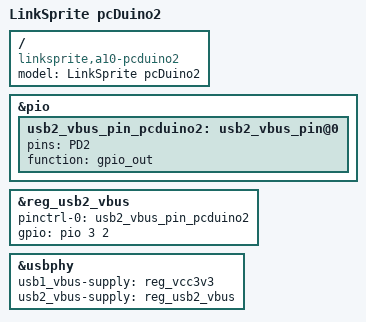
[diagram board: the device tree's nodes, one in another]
/*
 * Copyright 2015 Siarhei Siamashka <siarhei.siamashka@gmail.com>
 *
 * This file is dual-licensed: you can use it either under the terms
 * of the GPL or the X11 license, at your option. Note that this dual
 * licensing only applies to this file, and not this project as a
 * whole.
 *
 *  a) This file is free software; you can redistribute it and/or
 *     modify it under the terms of the GNU General Public License as
 *     published by the Free Software Foundation; either version 2 of the
 *     License, or (at your option) any later version.
 *
 *     This file is distributed in the hope that it will be useful,
 *     but WITHOUT ANY WARRANTY; without even the implied warranty of
 *     MERCHANTABILITY or FITNESS FOR A PARTICULAR PURPOSE.  See the
 *     GNU General Public License for more details.
 *
 * Or, alternatively,
 *
 *  b) Permission is hereby granted, free of charge, to any person
 *     obtaining a copy of this software and associated documentation
 *     files (the "Software"), to deal in the Software without
 *     restriction, including without limitation the rights to use,
 *     copy, modify, merge, publish, distribute, sublicense, and/or
 *     sell copies of the Software, and to permit persons to whom the
 *     Software is furnished to do so, subject to the following
 *     conditions:
 *
 *     The above copyright notice and this permission notice shall be
 *     included in all copies or substantial portions of the Software.
 *
 *     THE SOFTWARE IS PROVIDED "AS IS", WITHOUT WARRANTY OF ANY KIND,
 *     EXPRESS OR IMPLIED, INCLUDING BUT NOT LIMITED TO THE WARRANTIES
 *     OF MERCHANTABILITY, FITNESS FOR A PARTICULAR PURPOSE AND
 *     NONINFRINGEMENT. IN NO EVENT SHALL THE AUTHORS OR COPYRIGHT
 *     HOLDERS BE LIABLE FOR ANY CLAIM, DAMAGES OR OTHER LIABILITY,
 *     WHETHER IN AN ACTION OF CONTRACT, TORT OR OTHERWISE, ARISING
 *     FROM, OUT OF OR IN CONNECTION WITH THE SOFTWARE OR THE USE OR
 *     OTHER DEALINGS IN THE SOFTWARE.
 */

/*
 * The LinkSprite pcDuino2 board is almost identical to the older
 * LinkSprite pcDuino1 board. The only software visible difference
 * is that the pcDuino2 board got a USB VBUS voltage regulator, which
 * is controlled by the PD2 pin (pulled-up by default). Also one of
 * the USB host ports has been replaced with a USB WIFI chip.
 */

#include "sun4i-a10-pcduino.dts"

/ {
	model = "LinkSprite pcDuino2";
	compatible = "linksprite,a10-pcduino2", "allwinner,sun4i-a10";
};

&pio {
	usb2_vbus_pin_pcduino2: usb2_vbus_pin@0 {
		pins = "PD2";
		function = "gpio_out";
	};
};

&reg_usb2_vbus {
	pinctrl-names = "default";
	pinctrl-0 = <&usb2_vbus_pin_pcduino2>;
	gpio = <&pio 3 2 GPIO_ACTIVE_HIGH>;
	status = "okay";
};

&usbphy {
	usb1_vbus-supply = <&reg_vcc3v3>; /* USB WIFI is always on */
	usb2_vbus-supply = <&reg_usb2_vbus>;
	status = "okay";
};
